# AST1080 register map
File version: 1.0
CPU: CM4 r0p1, little endian, MPU, FPU, 4 interrupt priority bits, 256 interrupts
Registers are 32-bit, read-write, reset 0x0 unless marked. A register's access mark holds for its fields unless they carry their own. Offsets are from the block's base; [hi:lo] are bit positions; lines under a group give offsets from that group; {n}, {i} and the like mark numbered series.

## usb20
Base 0x00000000
Same registers: usb201 0x74122000
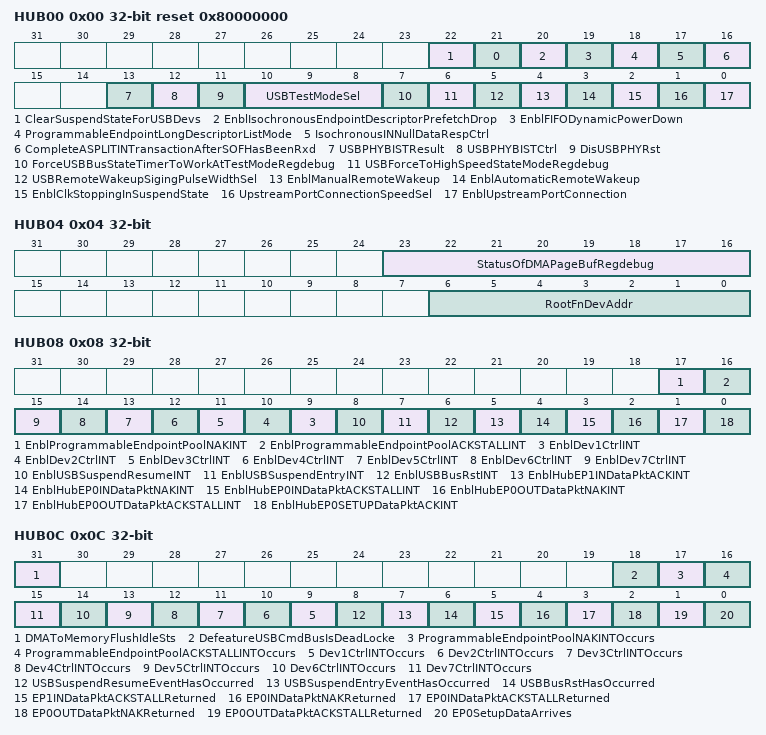
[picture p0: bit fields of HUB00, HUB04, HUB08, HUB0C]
0x00 HUB00 reset 0x80000000 — Root Function Control And Status Register
  [22] ClearSuspendStateForUSBDevs — Clear suspend state for USB devices
  [21] 0 — disable
  [20] EnblIsochronousEndpointDescriptorPrefetchDrop — Enable isochronous endpoint descriptor prefetch drop
  [19] EnblFIFODynamicPowerDown — Enable FIFO dynamic power down
  [18] ProgrammableEndpointLongDescriptorListMode
  [17] IsochronousINNullDataRespCtrl — Isochronous IN null data response control
  [16] CompleteASPLITINTransactionAfterSOFHasBeenRxd — Complete a "SPLIT IN Transaction" after SOF has been received
  [13] USBPHYBISTResult ro
  [12] USBPHYBISTCtrl — USB PHY BIST control
  [11] DisUSBPHYRst — Disable USB PHY reset
  [10:8] USBTestModeSel — USB Test Mode selection
  [7] ForceUSBBusStateTimerToWorkAtTestModeRegdebug
  [6] USBForceToHighSpeedStateModeRegdebug
  [5] USBRemoteWakeupSigingPulseWidthSel — USB Remote Wakeup signaling pulse width selection
  [4] EnblManualRemoteWakeup — Enable manual Remote Wakeup
  [3] EnblAutomaticRemoteWakeup — Enable automatic Remote Wakeup
  [2] EnblClkStoppingInSuspendState — Enable clock stopping in suspend state
  [1] UpstreamPortConnectionSpeedSel — Upstream port connection speed selection
  [0] EnblUpstreamPortConnection — Enable upstream port connection
0x04 HUB04 — Root Configuration Setting Register
  [23:16] StatusOfDMAPageBufRegdebug ro — Status of DMA page buffer regdebug
  [6:0] RootFnDevAddr — Root function device address
0x08 HUB08 — Interrupt Control Register
  [17] EnblProgrammableEndpointPoolNAKINT — Enable Programmable Endpoint Pool NAK Interrupt
  [16] EnblProgrammableEndpointPoolACKSTALLINT — Enable Programmable Endpoint Pool ACK/STALL Interrupt
  [n+8] EnblDev{n}CtrlINT (n=1..7) — Enable Device #{n} Controller Interrupt
  [8] EnblUSBSuspendResumeINT — Enable USB Suspend Resume Interrupt
  [7] EnblUSBSuspendEntryINT — Enable USB Suspend Entry Interrupt
  [6] EnblUSBBusRstINT — Enable USB Bus Reset Interrupt
  [5] EnblHubEP1INDataPktACKINT — Enable Hub EP1 IN Data packet ACK Interrupt
  [4] EnblHubEP0INDataPktNAKINT — Enable Hub EP0 IN Data packet NAK Interrupt
  [3] EnblHubEP0INDataPktACKSTALLINT — Enable Hub EP0 IN Data packet ACK/STALL Interrupt
  [2] EnblHubEP0OUTDataPktNAKINT — Enable Hub EP0 OUT Data packet NAK Interrupt
  [1] EnblHubEP0OUTDataPktACKSTALLINT — Enable Hub EP0 OUT Data packet ACK/STALL Interrupt
  [0] EnblHubEP0SETUPDataPktACKINT — Enable Hub EP0 SETUP Data packet ACK Interrupt
0x0C HUB0C — Interrupt Status Register
  [31] DMAToMemoryFlushIdleSts ro — DMA to Memory flush idle status
  [18] DefeatureUSBCmdBusIsDeadLocke ro — defeatureUSB command bus is dead locke
  [17] ProgrammableEndpointPoolNAKINTOccurs ro — Programmable Endpoint Pool NAK Interrupt Occurs
  [16] ProgrammableEndpointPoolACKSTALLINTOccurs ro — Programmable Endpoint Pool ACK/STALL Interrupt Occurs
  [n+8] Dev{n}CtrlINTOccurs ro (n=1..7) — Device #{n} Controller Interrupt Occurs
  [8] USBSuspendResumeEventHasOccurred
  [7] USBSuspendEntryEventHasOccurred
  [6] USBBusRstHasOccurred — USB Bus Reset has Occurred
  [5] EP1INDataPktACKSTALLReturned — EP1 IN Data Packet ACK/STALL Returned
  [4] EP0INDataPktNAKReturned — EP0 IN Data Packet NAK Returned
  [3] EP0INDataPktACKSTALLReturned — EP0 IN Data Packet ACK/STALL Returned
  [2] EP0OUTDataPktNAKReturned — EP0 OUT Data Packet NAK Returned
  [1] EP0OUTDataPktACKSTALLReturned — EP0 OUT Data Packet ACK/STALL Returned
  [0] EP0SetupDataArrives
0x10 HUB10 — Programmable Endpoint Pool ACK Interrupt Enable Register
  [20:0] ProgrammableEndpointACKINTEnbl — Programmable Endpoint ACK Interrupt Enable
0x14 HUB14 — Programmable Endpoint Pool NAK Interrupt Enable Register
  [20:0] ProgrammableEndpointNAKINTEnbl — Programmable Endpoint NAK Interrupt Enable
0x18 HUB18 — Programmable Endpoint Pool ACK Interrupt Status Register
  [20:0] ProgrammableEndpointACKINTOccurs — Programmable Endpoint ACK Interrupt Occurs
0x1C HUB1C (reset mask 0xFFFFF) — Programmable Endpoint Pool NAK Interrupt Status Register
  [20:0] ProgrammableEndpointNAKINTOccurs — Programmable Endpoint NAK Interrupt Occurs
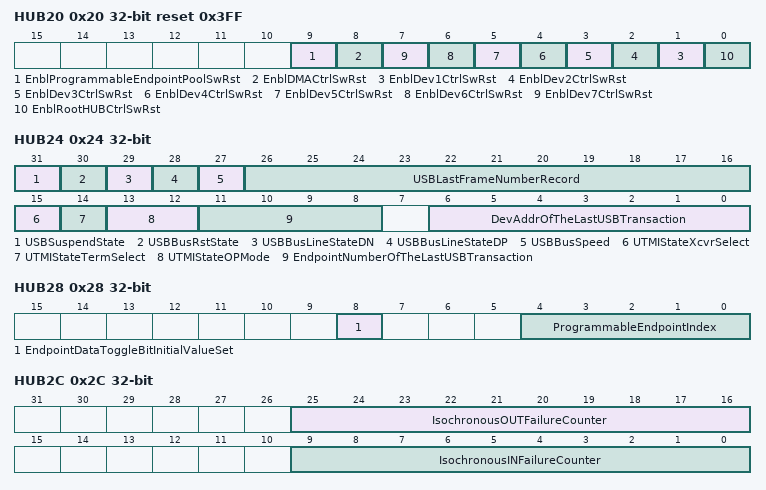
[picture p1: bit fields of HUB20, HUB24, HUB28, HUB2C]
0x20 HUB20 reset 0x3FF — Device Controller Soft Reset Enable Register
  [9] EnblProgrammableEndpointPoolSwRst — Enable Programmable Endpoint Pool software Reset
  [8] EnblDMACtrlSwRst — Enable DMA Controller software Reset
  [n] EnblDev{n}CtrlSwRst (n=1..7) — Enable Device #{n} Controller software Reset
  [0] EnblRootHUBCtrlSwRst — Enable Root HUB Controller software Reset
0x24 HUB24 — USB Status Register egdebugh
  [31] USBSuspendState ro
  [30] USBBusRstState ro — USB Bus Reset State
  [29] USBBusLineStateDN ro
  [28] USBBusLineStateDP ro
  [27] USBBusSpeed ro
  [26:16] USBLastFrameNumberRecord ro
  [15] UTMIStateXcvrSelect ro
  [14] UTMIStateTermSelect ro
  [13:12] UTMIStateOPMode ro
  [11:8] EndpointNumberOfTheLastUSBTransaction ro
  [6:0] DevAddrOfTheLastUSBTransaction ro — Device Address of the Last USB Transaction
0x28 HUB28 — Programmable Endpoint Pool Data Toggle Value Set
  [8] EndpointDataToggleBitInitialValueSet, [4:0] ProgrammableEndpointIndex
0x2C HUB2C — Isochronous Transaction Fail Accumulator egdebugh
  [25:16] IsochronousOUTFailureCounter, [9:0] IsochronousINFailureCounter
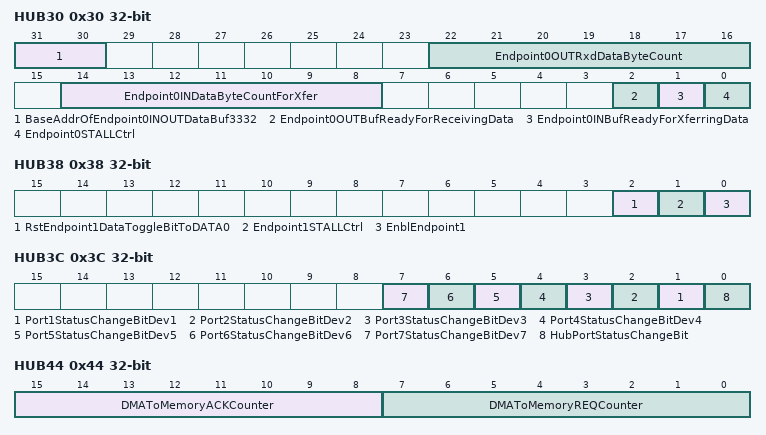
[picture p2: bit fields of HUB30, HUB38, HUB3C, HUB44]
0x30 HUB30 — Endpoint 0 Control/Status Register
  [31:30] BaseAddrOfEndpoint0INOUTDataBuf3332 — Base address of Endpoint 0 IN/OUT data buffer[33:32]
  [22:16] Endpoint0OUTRxdDataByteCount ro — Endpoint 0 OUT received data byte count
  [14:8] Endpoint0INDataByteCountForXfer — Endpoint 0 IN data byte count for transfer
  [2] Endpoint0OUTBufReadyForReceivingData — Endpoint 0 OUT buffer ready for receiving data
  [1] Endpoint0INBufReadyForXferringData — Endpoint 0 IN buffer ready for transferring data
  [0] Endpoint0STALLCtrl — Endpoint 0 STALL control
0x34 HUB34 — Base Address of Endpoint 0 IN/OUT Data Buffer Register
  [31:0] BaseAddrOfEndpoint0INOUTDataBuf — Base address of Endpoint 0 IN/OUT data buffer
0x38 HUB38 — Endpoint 1 Control/Status Register
  [2] RstEndpoint1DataToggleBitToDATA0 — Reset Endpoint 1 data toggle bit to DATA0
  [1] Endpoint1STALLCtrl — Endpoint 1 STALL control
  [0] EnblEndpoint1 — Enable Endpoint 1
0x3C HUB3C — Endpoint 1 Status Change Bitmap Data
  [n] Port{n}StatusChangeBitDev{n} (n=1..7) — Port #{n} Status Change Bit (Device #{n})
  [0] HubPortStatusChangeBit
0x40 HUB40 — SOF Counter
  [31:0] SOFCounter
0x44 HUB44 — DMA to Memory Synchronization Status
  [15:8] DMAToMemoryACKCounter ro, [7:0] DMAToMemoryREQCounter ro
{0x80+8i} SETUP[{i}] (i=0..7) group
  0x00 SETUPBUFF0 — Root Device SETUP Data Buffer
    [31:0] Data — Setup Data
  0x04 SETUPBUFF1 — Root Device SETUP Data Buffer
    [31:0] Data — Setup Data
{0x100+0x10*i} DEV[{i}] (i=0..6) group
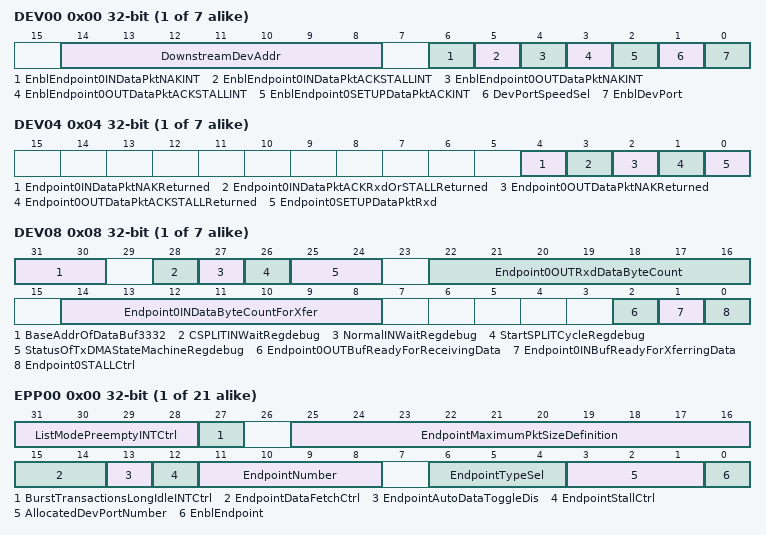
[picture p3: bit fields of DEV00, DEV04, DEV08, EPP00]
  0x00 DEV00 — Downstream Device Function Enable Control Register
    [14:8] DownstreamDevAddr — Downstream Device Address
    [6] EnblEndpoint0INDataPktNAKINT — Enable Endpoint 0 IN data packet NAK interrupt
    [5] EnblEndpoint0INDataPktACKSTALLINT — Enable Endpoint 0 IN data packet ACK/STALL interrupt
    [4] EnblEndpoint0OUTDataPktNAKINT — Enable Endpoint 0 OUT data packet NAK interrupt
    [3] EnblEndpoint0OUTDataPktACKSTALLINT — Enable Endpoint 0 OUT data packet ACK/STALL interrupt
    [2] EnblEndpoint0SETUPDataPktACKINT — Enable Endpoint 0 SETUP data packet ACK interrupt
    [1] DevPortSpeedSel — Device port speed selection
    [0] EnblDevPort — Enable device port
  0x04 DEV04 — Interrupt Status
    [4] Endpoint0INDataPktNAKReturned — Endpoint 0 IN data packet NAK returned
    [3] Endpoint0INDataPktACKRxdOrSTALLReturned — Endpoint 0 IN data packet ACK received or STALL returned
    [2] Endpoint0OUTDataPktNAKReturned — Endpoint 0 OUT data packet NAK returned
    [1] Endpoint0OUTDataPktACKSTALLReturned — Endpoint 0 OUT data packet ACK/STALL returned
    [0] Endpoint0SETUPDataPktRxd — Endpoint 0 SETUP data packet received
  0x08 DEV08 — Endpoint 0 Control/Status Register
    [31:30] BaseAddrOfDataBuf3332 — Base address of data buffer[33:32]
    [28] CSPLITINWaitRegdebug ro
    [27] NormalINWaitRegdebug ro
    [26] StartSPLITCycleRegdebug ro
    [25:24] StatusOfTxDMAStateMachineRegdebug ro — Status of Transmit DMA State Machine regdebug
    [22:16] Endpoint0OUTRxdDataByteCount ro — Endpoint 0 OUT received data byte count
    [14:8] Endpoint0INDataByteCountForXfer — Endpoint 0 IN data byte count for transfer
    [2] Endpoint0OUTBufReadyForReceivingData — Endpoint 0 OUT buffer ready for receiving data
    [1] Endpoint0INBufReadyForXferringData — Endpoint 0 IN buffer ready for transferring data
    [0] Endpoint0STALLCtrl — Endpoint 0 STALL control
  0x0C DEV0C — Base Address of Endpoint 0 IN/OUT Data Buffer Register
    [31:0] BaseAddrOfDataBuf310 — Base address of data buffer[31:0]
{0x200+0x10*i} EPP[{i}] (i=0..20) group
  0x00 EPP00 — Endpoint Configuration Register
    [31:28] ListModePreemptyINTCtrl — List mode pre-empty interrupt control
    [27] BurstTransactionsLongIdleINTCtrl — Burst transactions long idle interrupt control
    [25:16] EndpointMaximumPktSizeDefinition — Endpoint Maximum Packet Size Definition
    [15:14] EndpointDataFetchCtrl — Endpoint Data Fetch Control
    [13] EndpointAutoDataToggleDis — Endpoint Auto Data Toggle Disable
    [12] EndpointStallCtrl — Endpoint Stall Control
    [11:8] EndpointNumber
    [6:4] EndpointTypeSel — Endpoint type selection
    [3:1] AllocatedDevPortNumber — Allocated Device Port Number
    [0] EnblEndpoint — Enable Endpoint
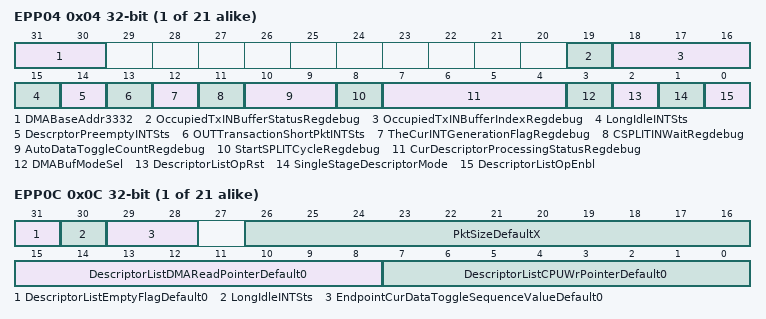
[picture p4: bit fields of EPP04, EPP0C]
  0x04 EPP04 — DMA Descriptor List Control/Status Register
    [31:30] DMABaseAddr3332 — DMA Base address[33:32]
    [19] OccupiedTxINBufferStatusRegdebug ro — Occupied Transmit IN Buffer Status regdebug
    [18:16] OccupiedTxINBufferIndexRegdebug ro — Occupied Transmit IN Buffer Index regdebug
    [15] LongIdleINTSts — Long idle interrupt status
    [14] DescrptorPreemptyINTSts — Descrptor pre-empty interrupt status
    [13] OUTTransactionShortPktINTSts — OUT transaction short packet interrupt status
    [12] TheCurINTGenerationFlagRegdebug ro — The Current Interrupt Generation Flag regdebug
    [11] CSPLITINWaitRegdebug ro
    [10:9] AutoDataToggleCountRegdebug ro
    [8] StartSPLITCycleRegdebug ro
    [7:4] CurDescriptorProcessingStatusRegdebug ro — Current Descriptor Processing Status regdebug
    [3] DMABufModeSel ro — DMA buffer mode selection
    [2] DescriptorListOpRst — Descriptor List Operation Reset
    [1] SingleStageDescriptorMode
    [0] DescriptorListOpEnbl — Descriptor List Operation Enable
  0x08 EPP08 — DMA Descriptor/Buffer Base Address
    [31:0] DMABaseAddr310 — DMA Base address[31:0]
  0x0C EPP0C — DMA Descriptor List Read(DMA)/Write(CPU) Pointer and Status
    [31] DescriptorListEmptyFlagDefault0 ro
    [30] LongIdleINTSts — Long idle interrupt status
    [29:28] EndpointCurDataToggleSequenceValueDefault0 — Endpoint Current Data Toggle Sequence Value (Default=0)
    [26:16] PktSizeDefaultX — Packet Size (Default=X)
    [15:8] DescriptorListDMAReadPointerDefault0
    [7:0] DescriptorListCPUWrPointerDefault0 — Descriptor List CPU Write Pointer (Default=0)
